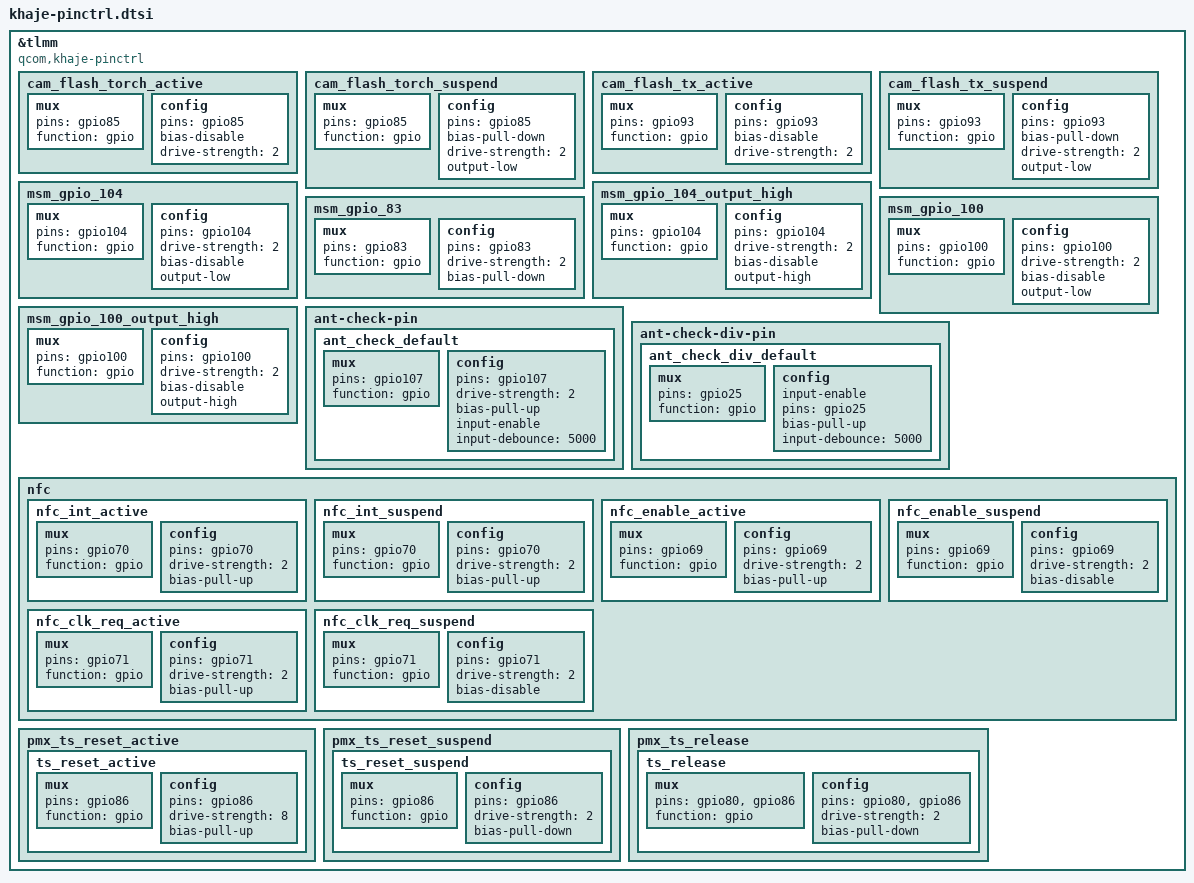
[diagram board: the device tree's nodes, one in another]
#include "bengal-pinctrl.dtsi"

&tlmm {
		compatible = "qcom,khaje-pinctrl";

		cam_flash_torch_active: cam_flash_torch_active {
			/* TORCH */
			mux {
				pins = "gpio85";
				function = "gpio";
			};

			config {
				pins = "gpio85";
				bias-disable; /* No PULL */
				drive-strength = <2>; /* 2 MA */
			};
		};

		cam_flash_torch_suspend: cam_flash_torch_suspend {
			/* TORCH */
			mux {
				pins = "gpio85";
				function = "gpio";
			};

			config {
				pins = "gpio85";
				bias-pull-down; /* PULL DOWN */
				drive-strength = <2>; /* 2 MA */
				output-low;
			};
		};

		cam_flash_tx_active: cam_flash_tx_active {
			/* TX */
			mux {
				pins = "gpio93";
				function = "gpio";
			};

			config {
				pins = "gpio93";
				bias-disable; /* No PULL */
				drive-strength = <2>; /* 2 MA */
			};
		};

		cam_flash_tx_suspend: cam_flash_tx_suspend {
			/* TX */
			mux {
				pins = "gpio93";
				function = "gpio";
			};

			config {
				pins = "gpio93";
				bias-pull-down; /* PULL DOWN */
				drive-strength = <2>; /* 2 MA */
				output-low;
			};
		};

                /* Spes Goodix Fingerprint pinctrl --start */
		msm_gpio_104:msm_gpio_104 {
			mux {
				pins = "gpio104";
				function = "gpio";
			};

			config {
				pins = "gpio104";
				drive-strength = <2>; /* 2 MA */
				bias-disable; /* No PULL */
				output-low;
			};
		};

		msm_gpio_104_output_high:msm_gpio_104_output_high {
			mux {
				pins = "gpio104";
				function = "gpio";
			};

			config {
				pins = "gpio104";
				drive-strength = <2>; /* 2 MA */
				bias-disable; /* No PULL */
				output-high;
			};
		};

		msm_gpio_83:msm_gpio_83 {
			mux {
				pins = "gpio83";
				function = "gpio";
			};

			config {
				pins = "gpio83";
				drive-strength = <2>; /* 2 MA */
				bias-pull-down; /* PULL DOWN */
			};
		};

		msm_gpio_100:msm_gpio_100 {
			mux {
				pins = "gpio100";
				function = "gpio";
			};		
		
			config {
				pins = "gpio100";
				drive-strength = <2>; /* 2 MA */
				bias-disable; /* No PULL */
				output-low;
			};
		};

		msm_gpio_100_output_high:msm_gpio_100_output_high {
			mux {
				pins = "gpio100";
				function = "gpio";
			};		
		
			config {
				pins = "gpio100";
				drive-strength = <2>; /* 2 MA */
				bias-disable; /* No PULL */
				output-high;
			};
		};
                /* Spes Goodix Fingerprint pinctrl --end */

		ant-check-pin {
		ant_check_default:
			ant_check_default {
				mux {
					pins = "gpio107";
					function = "gpio";
				};			

				config {
					pins = "gpio107";
					drive-strength = <2>;
					bias-pull-up;
					input-enable;
					input-debounce = <5000>;
				};
			};
		};

		ant-check-div-pin {
		ant_check_div_default:
			ant_check_div_default {
				mux {
					pins = "gpio25";
					function = "gpio";
				};
			
				config {
					input-enable;
					pins = "gpio25";
					bias-pull-up;
					input-debounce = <5000>;
				};
			};
		};

	nfc {
	                /* Spes NFC pinctrl --start */
			nfc_int_active {
				/* active state */
				mux {
					/* GPIO 70: NFC CLOCK REQUEST */				
					pins = "gpio70";
					function = "gpio";
					};

				config {
					pins = "gpio70";
					drive-strength = <2>; /* 2 MA */
					bias-pull-up;
					};
			};

			nfc_int_suspend {
				/* sleep state */
				mux {
					/* GPIO 70: NFC CLOCK REQUEST */				
					pins = "gpio70";
					function = "gpio";
					};

				config {
					pins = "gpio70";
					drive-strength = <2>; /* 2 MA */
					bias-pull-up;
					};
			};

			nfc_enable_active {
				/* active state */
				mux {
					/* GPIO 69: NFC CLOCK REQUEST */				
					pins = "gpio69";
					function = "gpio";
					};

				config {
					pins = "gpio69";
					drive-strength = <2>; /* 2 MA */
					bias-pull-up;
					};
			};

			nfc_enable_suspend {
				/* sleep state */
				mux {
					/* GPIO 69: NFC CLOCK REQUEST */				
					pins = "gpio69";
					function = "gpio";
					};

				config {
					pins = "gpio69";
					drive-strength = <2>; /* 2 MA */
					bias-disable;
					};
			};
	                /* Spes NFC pinctrl --end */
			nfc_clk_req_active {
				/* active state */
				mux {
					/* GPIO 71: NFC CLOCK REQUEST */
					pins = "gpio71";
					function = "gpio";
				};

				config {
					pins = "gpio71";
					drive-strength = <2>; /* 2 MA */
					bias-pull-up;
				};
			};

			nfc_clk_req_suspend {
				/* sleep state */
				mux {
					/* GPIO 71: NFC CLOCK REQUEST */
					pins = "gpio71";
					function = "gpio";
				};

				config {
					pins = "gpio71";
					drive-strength = <2>; /* 2 MA */
					bias-disable;
				};
			};
	};

		pmx_ts_reset_active {
			ts_reset_active: ts_reset_active {
				mux {
					pins = "gpio86";
					function = "gpio";
				};

				config {
					pins = "gpio86";
					drive-strength = <8>;
					bias-pull-up;
				};
			};
		};

		pmx_ts_reset_suspend {
			ts_reset_suspend: ts_reset_suspend {
				mux {
					pins = "gpio86";
					function = "gpio";
				};

				config {
					pins = "gpio86";
					drive-strength = <2>;
					bias-pull-down;
				};
			};
		};

		pmx_ts_release {
			ts_release: ts_release {
				mux {
					pins = "gpio80", "gpio86";
					function = "gpio";
				};

				config {
					pins = "gpio80", "gpio86";
					drive-strength = <2>;
					bias-pull-down;
			};
		};
	};
};
